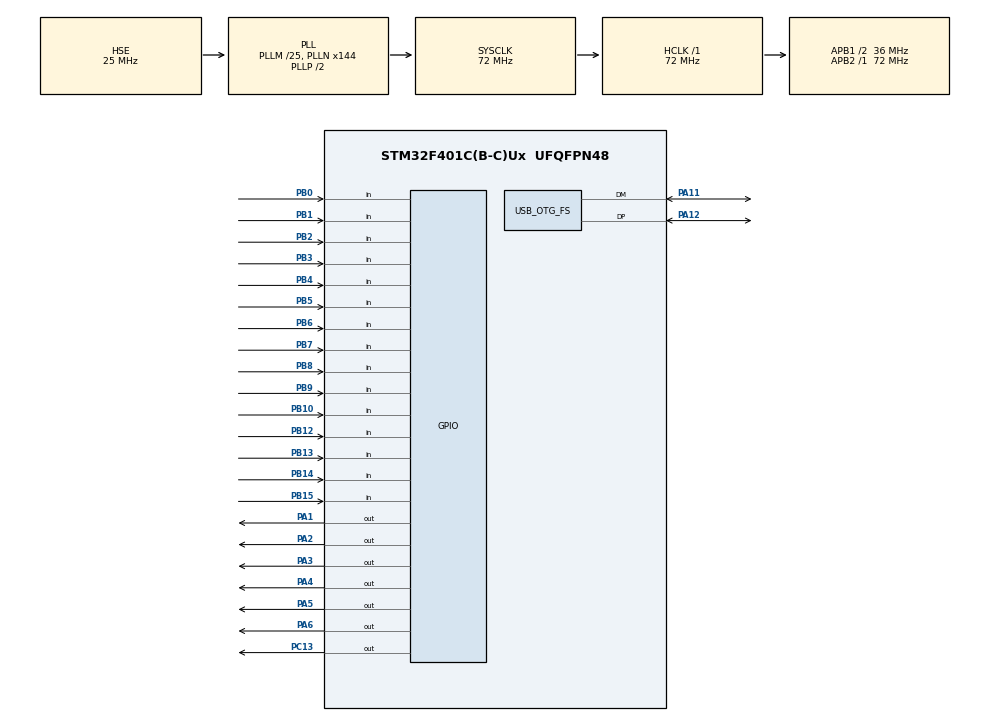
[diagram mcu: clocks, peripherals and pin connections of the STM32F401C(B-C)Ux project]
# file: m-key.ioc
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Mcu.Family=STM32F4
Mcu.Name=STM32F401C(B-C)Ux
Mcu.Package=UFQFPN48
NVIC.OTG_FS_IRQn=true\:0\:0\:false\:false\:true\:false\:true\:true
NVIC.PriorityGroup=NVIC_PRIORITYGROUP_4
PA1.GPIO_PuPd=GPIO_PULLDOWN
PA1.Signal=GPIO_Output
PA11.Mode=Device_Only
PA11.Signal=USB_OTG_FS_DM
PA12.Mode=Device_Only
PA12.Signal=USB_OTG_FS_DP
PA13.Mode=Serial_Wire
PA13.Signal=SYS_JTMS-SWDIO
PA14.Mode=Serial_Wire
PA14.Signal=SYS_JTCK-SWCLK
PA2.GPIO_PuPd=GPIO_PULLDOWN
PA2.Signal=GPIO_Output
PA3.GPIO_PuPd=GPIO_PULLDOWN
PA3.Signal=GPIO_Output
PA4.GPIO_PuPd=GPIO_PULLDOWN
PA4.Signal=GPIO_Output
PA5.GPIO_PuPd=GPIO_PULLDOWN
PA5.Signal=GPIO_Output
PA6.GPIO_PuPd=GPIO_PULLDOWN
PA6.Signal=GPIO_Output
PB0.GPIO_PuPd=GPIO_PULLDOWN
PB0.Signal=GPIO_Input
PB1.GPIO_PuPd=GPIO_PULLDOWN
PB1.Signal=GPIO_Input
PB10.GPIO_PuPd=GPIO_PULLDOWN
PB10.Signal=GPIO_Input
PB12.GPIO_PuPd=GPIO_PULLDOWN
PB12.Signal=GPIO_Input
PB13.GPIO_PuPd=GPIO_PULLDOWN
PB13.Signal=GPIO_Input
PB14.GPIO_PuPd=GPIO_PULLDOWN
PB14.Signal=GPIO_Input
PB15.GPIO_PuPd=GPIO_PULLDOWN
PB15.Signal=GPIO_Input
PB2.GPIO_PuPd=GPIO_PULLDOWN
PB2.Signal=GPIO_Input
PB3.GPIO_PuPd=GPIO_PULLDOWN
PB3.Signal=GPIO_Input
PB4.GPIO_PuPd=GPIO_PULLDOWN
PB4.Signal=GPIO_Input
PB5.GPIO_PuPd=GPIO_PULLDOWN
PB5.Signal=GPIO_Input
PB6.GPIO_PuPd=GPIO_PULLDOWN
PB6.Signal=GPIO_Input
PB7.GPIO_PuPd=GPIO_PULLDOWN
PB7.Signal=GPIO_Input
PB8.GPIO_PuPd=GPIO_PULLDOWN
PB8.Signal=GPIO_Input
PB9.GPIO_PuPd=GPIO_PULLDOWN
PB9.Signal=GPIO_Input
PC13-ANTI_TAMP.GPIO_PuPd=GPIO_NOPULL
PC13-ANTI_TAMP.PinState=GPIO_PIN_RESET
PC13-ANTI_TAMP.Signal=GPIO_Output
PH0\ -\ OSC_IN.Mode=HSE-External-Oscillator
PH0\ -\ OSC_IN.Signal=RCC_OSC_IN
PH1\ -\ OSC_OUT.Mode=HSE-External-Oscillator
PH1\ -\ OSC_OUT.Signal=RCC_OSC_OUT
ProjectManager.HeapSize=0x200
ProjectManager.StackSize=0x400
ProjectManager.TargetToolchain=Makefile
RCC.48MHZClocksFreq_Value=48000000
RCC.AHBFreq_Value=72000000
RCC.APB1CLKDivider=RCC_HCLK_DIV2
RCC.APB1Freq_Value=36000000
RCC.APB1TimFreq_Value=72000000
RCC.APB2Freq_Value=72000000
RCC.APB2TimFreq_Value=72000000
RCC.CortexFreq_Value=72000000
RCC.HCLKFreq_Value=72000000
RCC.HSE_VALUE=25000000
RCC.HSI_VALUE=16000000
RCC.LSE_VALUE=32768
RCC.PLLM=25
RCC.PLLN=144
RCC.PLLQ=3
RCC.SYSCLKFreq_VALUE=72000000
RCC.SYSCLKSource=RCC_SYSCLKSOURCE_PLLCLK
RCC.VCOOutputFreq_Value=144000000
USB_DEVICE.CLASS_NAME_FS=HID
USB_DEVICE.MANUFACTURER_STRING=Morel
USB_DEVICE.PRODUCT_STRING_HID_FS=STM32 m-key
USB_DEVICE.VirtualMode=Hid
USB_DEVICE.VirtualModeFS=Hid_FS
USB_OTG_FS.VirtualMode=Device_Only
VP_USB_DEVICE_VS_USB_DEVICE_HID_FS.Mode=HID_FS
board=custom

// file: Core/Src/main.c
/* USER CODE BEGIN Header */
/**
  ******************************************************************************
  * @file           : main.c
  * @brief          : Main program body
  ******************************************************************************
  * @attention
  *
  * Copyright (c) 2023 STMicroelectronics.
  * All rights reserved.
  *
  * This software is licensed under terms that can be found in the LICENSE file
  * in the root directory of this software component.
  * If no LICENSE file comes with this software, it is provided AS-IS.
  *
  ******************************************************************************
  */
/* USER CODE END Header */
#include "main.h"
#include "usb_device.h"

/* USER CODE BEGIN Includes */
#include "core.h"

/* USER CODE END Includes */

void SystemClock_Config(void);
static void MX_GPIO_Init(void);

int main(void)
{

  /* MCU Configuration--------------------------------------------------------*/

  /* Reset of all peripherals, Initializes the Flash interface and the Systick. */
  HAL_Init();

  /* Configure the system clock */
  SystemClock_Config();

  /* Initialize all configured peripherals */
  MX_GPIO_Init();
  MX_USB_DEVICE_Init();
  /* USER CODE BEGIN 2 */
  user_main();
  /* It will never reach the while */

  /* USER CODE END 2 */

  /* Infinite loop */
  while (1)
  {

  }
}

void SystemClock_Config(void)
{
  RCC_OscInitTypeDef RCC_OscInitStruct = {0};
  RCC_ClkInitTypeDef RCC_ClkInitStruct = {0};

  /** Configure the main internal regulator output voltage
  */
  __HAL_RCC_PWR_CLK_ENABLE();
  __HAL_PWR_VOLTAGESCALING_CONFIG(PWR_REGULATOR_VOLTAGE_SCALE2);

  /** Initializes the RCC Oscillators according to the specified parameters
  * in the RCC_OscInitTypeDef structure.
  */
  RCC_OscInitStruct.OscillatorType = RCC_OSCILLATORTYPE_HSE;
  RCC_OscInitStruct.HSEState = RCC_HSE_ON;
  RCC_OscInitStruct.PLL.PLLState = RCC_PLL_ON;
  RCC_OscInitStruct.PLL.PLLSource = RCC_PLLSOURCE_HSE;
  RCC_OscInitStruct.PLL.PLLM = 25;
  RCC_OscInitStruct.PLL.PLLN = 144;
  RCC_OscInitStruct.PLL.PLLP = RCC_PLLP_DIV2;
  RCC_OscInitStruct.PLL.PLLQ = 3;
  if (HAL_RCC_OscConfig(&RCC_OscInitStruct) != HAL_OK)
  {
    Error_Handler();
  }

  /** Initializes the CPU, AHB and APB buses clocks
  */
  RCC_ClkInitStruct.ClockType = RCC_CLOCKTYPE_HCLK|RCC_CLOCKTYPE_SYSCLK
                              |RCC_CLOCKTYPE_PCLK1|RCC_CLOCKTYPE_PCLK2;
  RCC_ClkInitStruct.SYSCLKSource = RCC_SYSCLKSOURCE_PLLCLK;
  RCC_ClkInitStruct.AHBCLKDivider = RCC_SYSCLK_DIV1;
  RCC_ClkInitStruct.APB1CLKDivider = RCC_HCLK_DIV2;
  RCC_ClkInitStruct.APB2CLKDivider = RCC_HCLK_DIV1;

  if (HAL_RCC_ClockConfig(&RCC_ClkInitStruct, FLASH_LATENCY_2) != HAL_OK)
  {
    Error_Handler();
  }
}

static void MX_GPIO_Init(void)
{
  GPIO_InitTypeDef GPIO_InitStruct = {0};

  /* GPIO Ports Clock Enable */
  __HAL_RCC_GPIOC_CLK_ENABLE();
  __HAL_RCC_GPIOH_CLK_ENABLE();
  __HAL_RCC_GPIOA_CLK_ENABLE();
  __HAL_RCC_GPIOB_CLK_ENABLE();

  /*Configure GPIO pin Output Level */
  HAL_GPIO_WritePin(GPIOC, GPIO_PIN_13, GPIO_PIN_RESET);

  /*Configure GPIO pin Output Level */
  HAL_GPIO_WritePin(GPIOA, GPIO_PIN_1|GPIO_PIN_2|GPIO_PIN_3|GPIO_PIN_4
                          |GPIO_PIN_5|GPIO_PIN_6, GPIO_PIN_RESET);

  /*Configure GPIO pin : PC13 */
  GPIO_InitStruct.Pin = GPIO_PIN_13;
  GPIO_InitStruct.Mode = GPIO_MODE_OUTPUT_PP;
  GPIO_InitStruct.Pull = GPIO_NOPULL;
  GPIO_InitStruct.Speed = GPIO_SPEED_FREQ_LOW;
  HAL_GPIO_Init(GPIOC, &GPIO_InitStruct);

  /*Configure GPIO pin : PA0 */
  GPIO_InitStruct.Pin = GPIO_PIN_0;
  GPIO_InitStruct.Mode = GPIO_MODE_IT_RISING;
  GPIO_InitStruct.Pull = GPIO_PULLUP;
  HAL_GPIO_Init(GPIOA, &GPIO_InitStruct);

  /*Configure GPIO pins : PA1 PA2 PA3 PA4
                           PA5 PA6 */
  GPIO_InitStruct.Pin = GPIO_PIN_1|GPIO_PIN_2|GPIO_PIN_3|GPIO_PIN_4
                          |GPIO_PIN_5|GPIO_PIN_6;
  GPIO_InitStruct.Mode = GPIO_MODE_OUTPUT_PP;
  GPIO_InitStruct.Pull = GPIO_PULLDOWN;
  GPIO_InitStruct.Speed = GPIO_SPEED_FREQ_LOW;
  HAL_GPIO_Init(GPIOA, &GPIO_InitStruct);

  /*Configure GPIO pins : PB0 PB1 PB2 PB10
                           PB12 PB13 PB14 PB15
                           PB3 PB4 PB5 PB6
                           PB7 PB8 PB9 */
  GPIO_InitStruct.Pin = GPIO_PIN_0|GPIO_PIN_1|GPIO_PIN_2|GPIO_PIN_10
                          |GPIO_PIN_12|GPIO_PIN_13|GPIO_PIN_14|GPIO_PIN_15
                          |GPIO_PIN_3|GPIO_PIN_4|GPIO_PIN_5|GPIO_PIN_6
                          |GPIO_PIN_7|GPIO_PIN_8|GPIO_PIN_9;
  GPIO_InitStruct.Mode = GPIO_MODE_INPUT;
  GPIO_InitStruct.Pull = GPIO_PULLDOWN;
  HAL_GPIO_Init(GPIOB, &GPIO_InitStruct);

}

void Error_Handler(void)
{
  __disable_irq();
  while (1)
  {
  }
}
